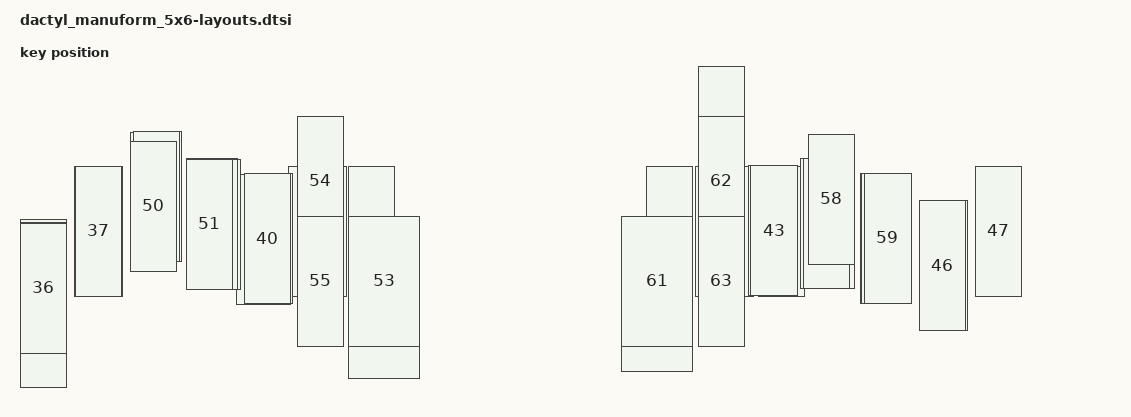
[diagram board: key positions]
// See https://zmk.dev/docs/development/hardware-integration/physical-layouts
// for how to configure this.

#include <physical_layouts.dtsi>

/ {
    physical_layout0: physical_layout_0 {
        compatible = "zmk,physical-layout";
        display-name = "Default Layout";
        transform = <&default_transform>;
        kscan = <&kscan0>;

        // Edit this to define the positions and sizes of the keys, or remove it
        // if your keyboard will not support ZMK Studio.
        // https://zmk.dev/docs/development/hardware-integration/physical-layouts#optional-keys-property
        keys  //                     w   h    x    y     rot    rx    ry
            = <&key_physical_attrs	100	268	1	83	0	0	0>
			, <&key_physical_attrs	100	268	108	-100	0	0	0>
			, <&key_physical_attrs	100	268	220	-168	0	0	0>
			, <&key_physical_attrs	100	268	333	-115	0	0	0>
			, <&key_physical_attrs	100	268	433	-84	0	0	0>
			, <&key_physical_attrs	100	268	536	-100	0	0	0>
			, <&key_physical_attrs	100	268	1374	-100	0	0	0>
			, <&key_physical_attrs	100	268	1477	-100	0	0	0>
			, <&key_physical_attrs	100	268	1577	-116	0	0	0>
			, <&key_physical_attrs	100	268	1690	-85	0	0	0>
			, <&key_physical_attrs	100	268	1802	-32	0	0	0>
			, <&key_physical_attrs	100	268	1910	-100	0	0	0>
			, <&key_physical_attrs	100	268	0	6	0	0	0>
			, <&key_physical_attrs	100	268	111	-100	0	0	0>
			, <&key_physical_attrs	100	268	227	-169	0	0	0>
			, <&key_physical_attrs	100	268	344	-115	0	0	0>
			, <&key_physical_attrs	100	268	448	-83	0	0	0>
			, <&key_physical_attrs	100	268	554	-100	0	0	0>
			, <&key_physical_attrs	100	268	1356	-100	0	0	0>
			, <&key_physical_attrs	100	268	1462	-101	0	0	0>
			, <&key_physical_attrs	100	268	1566	-116	0	0	0>
			, <&key_physical_attrs	100	268	1683	-85	0	0	0>
			, <&key_physical_attrs	100	268	1799	-31	0	0	0>
			, <&key_physical_attrs	100	268	1910	-100	0	0	0>
			, <&key_physical_attrs	100	268	0	13	0	0	0>
			, <&key_physical_attrs	100	268	113	-100	0	0	0>
			, <&key_physical_attrs	100	268	230	-169	0	0	0>
			, <&key_physical_attrs	100	268	348	-114	0	0	0>
			, <&key_physical_attrs	100	268	453	-85	0	0	0>
			, <&key_physical_attrs	100	268	560	-99	0	0	0>
			, <&key_physical_attrs	100	268	1350	-100	0	0	0>
			, <&key_physical_attrs	100	268	1457	-101	0	0	0>
			, <&key_physical_attrs	100	268	1562	-115	0	0	0>
			, <&key_physical_attrs	100	268	1680	-86	0	0	0>
			, <&key_physical_attrs	100	268	1798	-31	0	0	0>
			, <&key_physical_attrs	100	268	1910	-100	0	0	0>
			, <&key_physical_attrs	100	268	0	14	0	0	0>
			, <&key_physical_attrs	100	268	111	-100	0	0	0>
			, <&key_physical_attrs	100	268	227	-169	0	0	0>
			, <&key_physical_attrs	100	268	344	-114	0	0	0>
			, <&key_physical_attrs	100	268	448	-85	0	0	0>
			, <&key_physical_attrs	100	268	554	-99	0	0	0>
			, <&key_physical_attrs	100	268	1356	-100	0	0	0>
			, <&key_physical_attrs	100	268	1462	-101	0	0	0>
			, <&key_physical_attrs	100	268	1566	-115	0	0	0>
			, <&key_physical_attrs	100	268	1683	-86	0	0	0>
			, <&key_physical_attrs	100	268	1799	-31	0	0	0>
			, <&key_physical_attrs	100	268	1910	-100	0	0	0>
			, <&key_physical_attrs	100	268	554	-12	0	0	0>
			, <&key_physical_attrs	100	268	657	-100	0	0	0>
			, <&key_physical_attrs	100	268	220	-150	0	0	0>
			, <&key_physical_attrs	100	268	333	-114	0	0	0>
			, <&key_physical_attrs	150	268	657	64	0	0	0>
			, <&key_physical_attrs	150	268	657	0	0	0	0>
			, <&key_physical_attrs	100	268	554	-200	0	0	0>
			, <&key_physical_attrs	100	268	554	0	0	0	0>
			, <&key_physical_attrs	100	268	1356	-300	0	0	0>
			, <&key_physical_attrs	100	268	1253	-100	0	0	0>
			, <&key_physical_attrs	100	268	1577	-164	0	0	0>
			, <&key_physical_attrs	100	268	1690	-86	0	0	0>
			, <&key_physical_attrs	150	268	1203	50	0	0	0>
			, <&key_physical_attrs	150	268	1203	0	0	0	0>
			, <&key_physical_attrs	100	268	1356	-200	0	0	0>
			, <&key_physical_attrs	100	268	1356	0	0	0	0>
            ;
    };
};
